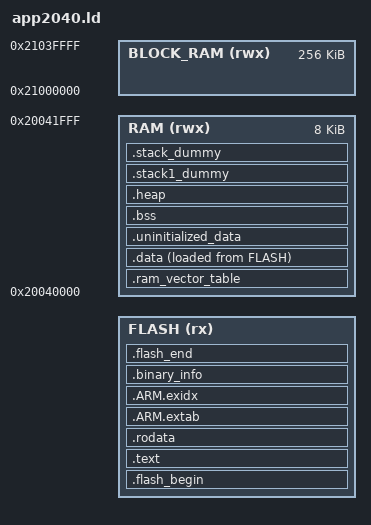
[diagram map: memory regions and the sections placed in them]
INCLUDE linker_definitions.ld

MEMORY
{
    FLASH(rx) : ORIGIN = __FLASH_APP_START, LENGTH = __FLASH_SLOT_LENGTH
    RAM(rwx) : ORIGIN = 0x20040000, LENGTH = 8k
    BLOCK_RAM(rwx) : ORIGIN =  0x21000000, LENGTH = 256k
}

ENTRY(_entry_point)

SECTIONS
{
    .flash_begin : {
        __flash_binary_start = .;
    } > FLASH

    .text : {
        __logical_binary_start = .;
        KEEP (*(.vectors))
        KEEP (*(.binary_info_header))
        __binary_info_header_end = .;
        KEEP (*(.reset))
        /* TODO revisit this now memset/memcpy/float in ROM */
        /* bit of a hack right now to exclude all floating point and time critical (e.g. memset, memcpy) code from
         * FLASH ... we will include any thing excluded here in .data below by default */
        *(.init)
        *(EXCLUDE_FILE(*libgcc.a: *libc.a:*lib_a-mem*.o *libm.a:) .text*)
        *(.fini)
        /* Pull all c'tors into .text */
        *crtbegin.o(.ctors)
        *crtbegin?.o(.ctors)
        *(EXCLUDE_FILE(*crtend?.o *crtend.o) .ctors)
        *(SORT(.ctors.*))
        *(.ctors)
        /* Followed by destructors */
        *crtbegin.o(.dtors)
        *crtbegin?.o(.dtors)
        *(EXCLUDE_FILE(*crtend?.o *crtend.o) .dtors)
        *(SORT(.dtors.*))
        *(.dtors)

        *(.eh_frame*)
        . = ALIGN(4);
    } > FLASH

    .rodata : {
        *(EXCLUDE_FILE(*libgcc.a: *libc.a:*lib_a-mem*.o *libm.a:) .rodata*)
        . = ALIGN(4);
        *(SORT_BY_ALIGNMENT(SORT_BY_NAME(.flashdata*)))
        . = ALIGN(4);
    } > FLASH

    .ARM.extab :
    {
        *(.ARM.extab* .gnu.linkonce.armextab.*)
    } > FLASH

    __exidx_start = .;
    .ARM.exidx :
    {
        *(.ARM.exidx* .gnu.linkonce.armexidx.*)
    } > FLASH
    __exidx_end = .;

    /* Machine inspectable binary information */
    . = ALIGN(4);
    __binary_info_start = .;
    .binary_info :
    {
        KEEP(*(.binary_info.keep.*))
        *(.binary_info.*)
    } > FLASH
    __binary_info_end = .;
    . = ALIGN(4);

   .ram_vector_table (NOLOAD): {
        *(.ram_vector_table)
    } > RAM

    .data : {
        __data_start__ = .;
        *(vtable)

        *(.time_critical*)

        /* remaining .text and .rodata; i.e. stuff we exclude above because we want it in RAM */
        *(.text*)
        . = ALIGN(4);
        *(.rodata*)
        . = ALIGN(4);

        *(.data*)

        . = ALIGN(4);
        *(.after_data.*)
        . = ALIGN(4);
        /* preinit data */
        PROVIDE_HIDDEN (__mutex_array_start = .);
        KEEP(*(SORT(.mutex_array.*)))
        KEEP(*(.mutex_array))
        PROVIDE_HIDDEN (__mutex_array_end = .);

        . = ALIGN(4);
        /* preinit data */
        PROVIDE_HIDDEN (__preinit_array_start = .);
        KEEP(*(SORT(.preinit_array.*)))
        KEEP(*(.preinit_array))
        PROVIDE_HIDDEN (__preinit_array_end = .);

        . = ALIGN(4);
        /* init data */
        PROVIDE_HIDDEN (__init_array_start = .);
        KEEP(*(SORT(.init_array.*)))
        KEEP(*(.init_array))
        PROVIDE_HIDDEN (__init_array_end = .);

        . = ALIGN(4);
        /* finit data */
        PROVIDE_HIDDEN (__fini_array_start = .);
        *(SORT(.fini_array.*))
        *(.fini_array)
        PROVIDE_HIDDEN (__fini_array_end = .);

        *(.jcr)
        . = ALIGN(4);
        /* All data end */
        __data_end__ = .;
    } > RAM AT> FLASH
    /* __etext is (for backwards compatibility) the name of the .data init source pointer (...) */
    __etext = LOADADDR(.data);

    .uninitialized_data (NOLOAD): {
        . = ALIGN(4);
        *(.uninitialized_data*)
    } > RAM

    __scratch_x_start__ = .;
    __scratch_x_end__ = .;
    __scratch_x_source__ = .;
    __scratch_y_start__ = .;
    __scratch_y_end__ = .;
    __scratch_y_source__ = .;

    .bss  : {
        . = ALIGN(4);
        __bss_start__ = .;
        *(SORT_BY_ALIGNMENT(SORT_BY_NAME(.bss*)))
        *(COMMON)
        . = ALIGN(4);
        __bss_end__ = .;
    } > RAM

    .heap (NOLOAD):
    {
        __end__ = .;
        end = __end__;
        KEEP(*(.heap*))
        __HeapLimit = .;
    } > RAM

    /* .stack*_dummy section doesn't contains any symbols. It is only
     * used for linker to calculate size of stack sections, and assign
     * values to stack symbols later
     *
     * stack1 section may be empty/missing if platform_launch_core1 is not used */

    .stack1_dummy (NOLOAD):
    {
        *(.stack1*)
    } > RAM

    .stack_dummy (NOLOAD):
    {
        __StackBottom = .;
        KEEP(*(.stack*))
        __StackTop = .;
    } > RAM

    .flash_end : {
        KEEP(*(.embedded_end_block*))
        /* Align binary size to 256 bytes */
        . = . + 1;
        . = ALIGN(256) - 1;
        BYTE(0);
        PROVIDE(__flash_binary_end = .);
    } > FLASH

    /* stack limit is poorly named, but historically is maximum heap ptr */
    __StackLimit = ORIGIN(RAM) + LENGTH(RAM);
    PROVIDE(__stack = __StackTop);

    /* Check if data + heap + stack exceeds RAM limit */
    ASSERT(__StackTop <= __StackLimit, "region RAM overflowed")

    ASSERT( __binary_info_header_end - __logical_binary_start <= 256, "Binary info must be in first 256 bytes of the binary")
    /* todo assert on extra code */
}

